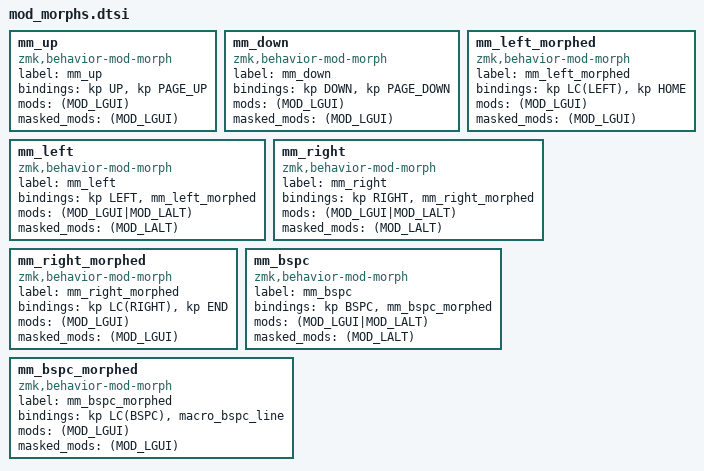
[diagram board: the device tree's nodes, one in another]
// @aumuell's modified mod-morph is used to swallow the held modifier
// https://github.com/aumuell/zmk/commit/fa61c6a3c6e7cbfcb5b3d9168b3454bf95c
// https://github.com/zmkfirmware/zmk/issues/683

// up
// gui + up = page up
mm_up: mm_up {
  compatible = "zmk,behavior-mod-morph";
  label = "mm_up";
  #binding-cells = <0>;
  bindings = <&kp UP>, <&kp PAGE_UP>;
  mods = <(MOD_LGUI)>;
  masked_mods = <(MOD_LGUI)>; // don't send held modifier
};

// down
// gui+down = page down
mm_down: mm_down {
  compatible = "zmk,behavior-mod-morph";
  label = "mm_down";
  #binding-cells = <0>;
  bindings = <&kp DOWN>, <&kp PAGE_DOWN>;
  mods = <(MOD_LGUI)>;
  masked_mods = <(MOD_LGUI)>; // don't send held modifier
};

// left
// gui+left = home
// alt+left = ctrl+left (word left)
mm_left: mm_left {
  compatible = "zmk,behavior-mod-morph";
  label = "mm_left";
  #binding-cells = <0>;
  bindings = <&kp LEFT>, <&mm_left_morphed>;
  mods = <(MOD_LGUI|MOD_LALT)>; // morph on GUI or ALT...
  masked_mods = <(MOD_LALT)>;   // but don't send ALT to the next mod-morph
};
mm_left_morphed: mm_left_morphed {
  compatible = "zmk,behavior-mod-morph";
  label = "mm_left_morphed";
  #binding-cells = <0>;
  bindings = <&kp LC(LEFT)>, <&kp HOME>;
  mods = <(MOD_LGUI)>;
  masked_mods = <(MOD_LGUI)>; // don't send gui
};

// right
// gui+right = end
// alt+right = ctrl+right (word right)
mm_right: mm_right {
  compatible = "zmk,behavior-mod-morph";
  label = "mm_right";
  #binding-cells = <0>;
  bindings = <&kp RIGHT>, <&mm_right_morphed>;
  mods = <(MOD_LGUI|MOD_LALT)>; // morph on GUI or ALT...
  masked_mods = <(MOD_LALT)>;   // but don't send ALT to the next mod-morph
};
mm_right_morphed: mm_right_morphed {
  compatible = "zmk,behavior-mod-morph";
  label = "mm_right_morphed";
  #binding-cells = <0>;
  bindings = <&kp LC(RIGHT)>, <&kp END>;
  mods = <(MOD_LGUI)>;
  masked_mods = <(MOD_LGUI)>; // don't send held modifier
};

// backspace
// alt+backspace = ctrl+backspace (delete word)
// super+backspace = delete to beginning of line
mm_bspc: mm_bspc {
  compatible = "zmk,behavior-mod-morph";
  label = "mm_bspc";
  #binding-cells = <0>;
  bindings = <&kp BSPC>, <&mm_bspc_morphed>;
  mods = <(MOD_LGUI|MOD_LALT)>; // morph on GUI or ALT...
  masked_mods = <(MOD_LALT)>;   // but don't send ALT to the next mod-morph
};
mm_bspc_morphed: mm_bspc_morphed {
  compatible = "zmk,behavior-mod-morph";
  label = "mm_bspc_morphed";
  #binding-cells = <0>;
  bindings = <&kp LC(BSPC)>, <&macro_bspc_line>;
  mods = <(MOD_LGUI)>;
  masked_mods = <(MOD_LGUI)>; // don't send held modifier
};
